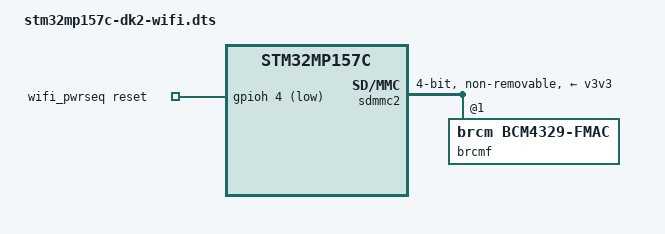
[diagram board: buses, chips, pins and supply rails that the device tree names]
/dts-v1/;

#include "stm32mp157c-dk2.dts"

/ {
	wifi_pwrseq: wifi-pwrseq {
		compatible = "mmc-pwrseq-simple";
		reset-gpios = <&gpioh 4 GPIO_ACTIVE_LOW>;
	};
};

/* Wifi */
&sdmmc2 {
	arm,primecell-periphid = <0x10153180>;
	pinctrl-names = "default", "opendrain", "sleep";
	pinctrl-0 = <&sdmmc2_b4_pins_a>;
	pinctrl-1 = <&sdmmc2_b4_od_pins_a>;
	pinctrl-2 = <&sdmmc2_b4_sleep_pins_a>;
	non-removable;
	st,neg-edge;
	bus-width = <4>;
	vmmc-supply = <&v3v3>;
	mmc-pwrseq = <&wifi_pwrseq>;
	#address-cells = <1>;
	#size-cells = <0>;
	status = "okay";

	brcmf: bcrmf@1 {
		reg = <1>;
		compatible = "brcm,bcm4329-fmac";
	};
};
